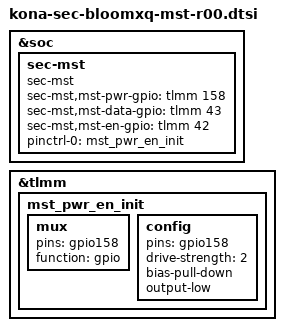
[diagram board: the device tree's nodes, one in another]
/* Copyright (c) 2019, Samsung Electronics Corporation. All rights reserved.
 *
 * This program is free software; you can redistribute it and/or modify
 * it under the terms of the GNU General Public License version 2 and
 * only version 2 as published by the Free Software Foundation.
 *
 * This program is distributed in the hope that it will be useful,
 * but WITHOUT ANY WARRANTY; without even the implied warranty of
 * MERCHANTABILITY or FITNESS FOR A PARTICULAR PURPOSE.  See the
 * GNU General Public License for more details.
 */
&soc {
	sec-mst {
		compatible = "sec-mst";
		sec-mst,mst-pwr-gpio = <&tlmm 158 0>;
		sec-mst,mst-data-gpio = <&tlmm 43 0>;
		sec-mst,mst-en-gpio = <&tlmm 42 0>;

		pinctrl-names = "default";
		pinctrl-0 = <&mst_pwr_en_init>;
	};
};

&tlmm {
	mst_pwr_en_init: mst_pwr_en_init {
		mux {
			pins = "gpio158";
			function = "gpio";
		};
		config {
			pins = "gpio158";
			drive-strength = <2>;
			bias-pull-down;
			output-low;
		};
	};
/*
	mst_data_init: mst_data_init {
		mux {
			pins = "gpio12";
			function = "gpio";
		};
		config {
			pins = "gpio12";
			drive-strength = <16>;
			bias-pull-down;
			output_low;
		};
	};
	mst_en_init: mst_en_init {
		mux {
			pins = "gpio11";
			function = "gpio";
		};
		config {
			pins = "gpio11";
			drive-strength = <16>;
			bias-pull-down;
			output_low;
		};
	};
*/
};
